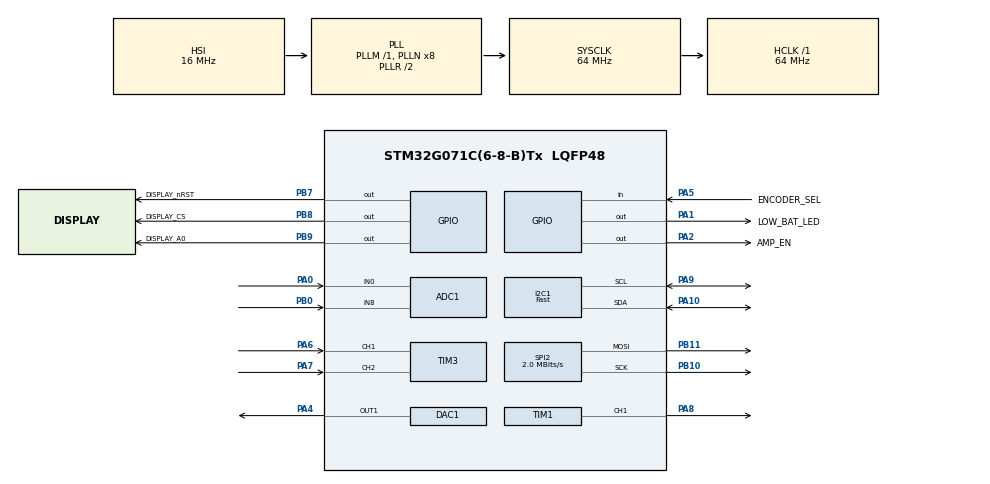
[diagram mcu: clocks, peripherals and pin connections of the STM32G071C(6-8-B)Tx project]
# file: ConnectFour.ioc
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ADC1.Channel-0\#ChannelRegularConversion=ADC_CHANNEL_0
ADC1.NbrOfConversionFlag=1
ADC1.Rank-0\#ChannelRegularConversion=1
ADC1.SamplingTime-0\#ChannelRegularConversion=ADC_SAMPLINGTIME_COMMON_1
ADC1.SamplingTimeCommon1=ADC_SAMPLETIME_160CYCLES_5
ADC1.SelectedChannel=ADC_CHANNEL_0|ADC_CHANNEL_8
ADC1.master=1
DAC1.DAC_Channel-DAC_OUT1=DAC_CHANNEL_1
DAC1.DAC_Trigger-DAC_OUT1=DAC_TRIGGER_T6_TRGO
Dma.DAC1_CH1.0.Direction=DMA_MEMORY_TO_PERIPH
Dma.DAC1_CH1.0.EventEnable=DISABLE
Dma.DAC1_CH1.0.Instance=DMA1_Channel1
Dma.DAC1_CH1.0.MemDataAlignment=DMA_MDATAALIGN_HALFWORD
Dma.DAC1_CH1.0.MemInc=DMA_MINC_ENABLE
Dma.DAC1_CH1.0.Mode=DMA_CIRCULAR
Dma.DAC1_CH1.0.PeriphDataAlignment=DMA_PDATAALIGN_HALFWORD
Dma.DAC1_CH1.0.PeriphInc=DMA_PINC_DISABLE
Dma.DAC1_CH1.0.Polarity=HAL_DMAMUX_REQ_GEN_RISING
Dma.DAC1_CH1.0.Priority=DMA_PRIORITY_HIGH
Dma.DAC1_CH1.0.RequestNumber=1
Dma.DAC1_CH1.0.SignalID=NONE
Dma.DAC1_CH1.0.SyncEnable=DISABLE
Dma.DAC1_CH1.0.SyncPolarity=HAL_DMAMUX_SYNC_NO_EVENT
Dma.DAC1_CH1.0.SyncRequestNumber=1
Dma.DAC1_CH1.0.SyncSignalID=NONE
Dma.Request0=DAC1_CH1
I2C1.I2C_Speed_Mode=I2C_Fast
I2C1.Timing=0x00C12166
Mcu.Family=STM32G0
Mcu.Name=STM32G071C(6-8-B)Tx
Mcu.Package=LQFP48
NVIC.DMA1_Channel1_IRQn=true\:0\:0\:false\:false\:true\:false\:true\:true
PA0.Mode=IN0
PA0.Signal=ADC1_IN0
PA1.GPIO_Label=LOW_BAT_LED
PA1.Signal=GPIO_Output
PA10.Mode=I2C
PA10.Signal=I2C1_SDA
PA13.Mode=Serial_Wire
PA13.Signal=SYS_SWDIO
PA14-BOOT0.Mode=Serial_Wire
PA14-BOOT0.Signal=SYS_SWCLK
PA2.GPIO_Label=AMP_EN
PA2.Signal=GPIO_Output
PA4.Signal=COMP_DAC11_group
PA5.GPIO_Label=ENCODER_SEL
PA5.Signal=GPIO_Input
PA6.Signal=S_TIM3_CH1
PA7.Signal=S_TIM3_CH2
PA8.Signal=S_TIM1_CH1
PA9.Mode=I2C
PA9.Signal=I2C1_SCL
PB0.Mode=IN8
PB0.Signal=ADC1_IN8
PB10.Mode=TX_Only_Simplex_Unidirect_Master
PB10.Signal=SPI2_SCK
PB11.Mode=TX_Only_Simplex_Unidirect_Master
PB11.Signal=SPI2_MOSI
PB7.GPIO_Label=DISPLAY_nRST
PB7.Signal=GPIO_Output
PB8.GPIO_Label=DISPLAY_CS
PB8.PinState=GPIO_PIN_SET
PB8.Signal=GPIO_Output
PB9.GPIO_Label=DISPLAY_A0
PB9.Signal=GPIO_Output
ProjectManager.HeapSize=0x200
ProjectManager.StackSize=0x1800
ProjectManager.TargetToolchain=CMake
RCC.ADCFreq_Value=64000000
RCC.AHBFreq_Value=64000000
RCC.CortexFreq_Value=64000000
RCC.EXTERNAL_CLOCK_VALUE=48000
RCC.HCLKFreq_Value=64000000
RCC.HSE_VALUE=8000000
RCC.HSI_VALUE=16000000
RCC.LSE_VALUE=32768
RCC.SYSCLKFreq_VALUE=64000000
RCC.SYSCLKSource=RCC_SYSCLKSOURCE_PLLCLK
RCC.VCOOutputFreq_Value=128000000
SH.COMP_DAC11_group.0=DAC1_OUT1,DAC_OUT1
SH.S_TIM1_CH1.0=TIM1_CH1,PWM Generation1 CH1
SH.S_TIM3_CH1.0=TIM3_CH1,Encoder_Interface
SH.S_TIM3_CH2.0=TIM3_CH2,Encoder_Interface
SPI2.BaudRatePrescaler=SPI_BAUDRATEPRESCALER_32
SPI2.CalculateBaudRate=2.0 MBits/s
SPI2.DataSize=SPI_DATASIZE_8BIT
SPI2.Direction=SPI_DIRECTION_2LINES
SPI2.Mode=SPI_MODE_MASTER
SPI2.NSSPMode=SPI_NSS_PULSE_DISABLE
SPI2.VirtualType=VM_MASTER
TIM1.AutoReloadPreload=TIM_AUTORELOAD_PRELOAD_ENABLE
TIM1.Channel-PWM\ Generation1\ CH1=TIM_CHANNEL_1
TIM1.Period=3199
TIM3.ClockDivision=TIM_CLOCKDIVISION_DIV4
TIM3.EncoderMode=TIM_ENCODERMODE_TI12
TIM3.IC1Filter=15
TIM3.IC2Filter=15
TIM6.AutoReloadPreload=TIM_AUTORELOAD_PRELOAD_ENABLE
TIM6.Period=3999
TIM6.TIM_MasterOutputTrigger=TIM_TRGO_UPDATE
VP_TIM1_VS_ClockSourceINT.Mode=Internal
VP_TIM6_VS_ClockSourceINT.Mode=Enable_Timer
board=custom

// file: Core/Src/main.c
/* USER CODE BEGIN Header */
/**
  ******************************************************************************
  * @file           : main.c
  * @brief          : Main program body
  ******************************************************************************
  * @attention
  *
  * Copyright (c) 2026 STMicroelectronics.
  * All rights reserved.
  *
  * This software is licensed under terms that can be found in the LICENSE file
  * in the root directory of this software component.
  * If no LICENSE file comes with this software, it is provided AS-IS.
  *
  ******************************************************************************
  */
/* USER CODE END Header */
#include "main.h"

/* USER CODE BEGIN Includes */
#include "app_main.h"
/* USER CODE END Includes */

ADC_HandleTypeDef hadc1;

DAC_HandleTypeDef hdac1;
DMA_HandleTypeDef hdma_dac1_ch1;

I2C_HandleTypeDef hi2c1;

SPI_HandleTypeDef hspi2;

TIM_HandleTypeDef htim1;
TIM_HandleTypeDef htim3;
TIM_HandleTypeDef htim6;

void SystemClock_Config(void);
static void MX_GPIO_Init(void);
static void MX_DMA_Init(void);
static void MX_ADC1_Init(void);
static void MX_DAC1_Init(void);
static void MX_I2C1_Init(void);
static void MX_SPI2_Init(void);
static void MX_TIM3_Init(void);
static void MX_TIM1_Init(void);
static void MX_TIM6_Init(void);

int main(void)
{

  /* MCU Configuration--------------------------------------------------------*/

  /* Reset of all peripherals, Initializes the Flash interface and the Systick. */
  HAL_Init();

  /* Configure the system clock */
  SystemClock_Config();

  /* Initialize all configured peripherals */
  MX_GPIO_Init();
  MX_DMA_Init();
  MX_ADC1_Init();
  MX_DAC1_Init();
  MX_I2C1_Init();
  MX_SPI2_Init();
  MX_TIM3_Init();
  MX_TIM1_Init();
  MX_TIM6_Init();
  /* USER CODE BEGIN 2 */
  app_main(); /* never returns */
  /* USER CODE END 2 */

  /* Infinite loop */
  while (1)
  {

  }
}

void SystemClock_Config(void)
{
  RCC_OscInitTypeDef RCC_OscInitStruct = {0};
  RCC_ClkInitTypeDef RCC_ClkInitStruct = {0};

  /** Configure the main internal regulator output voltage
  */
  HAL_PWREx_ControlVoltageScaling(PWR_REGULATOR_VOLTAGE_SCALE1);

  /** Initializes the RCC Oscillators according to the specified parameters
  * in the RCC_OscInitTypeDef structure.
  */
  RCC_OscInitStruct.OscillatorType = RCC_OSCILLATORTYPE_HSI;
  RCC_OscInitStruct.HSIState = RCC_HSI_ON;
  RCC_OscInitStruct.HSIDiv = RCC_HSI_DIV1;
  RCC_OscInitStruct.HSICalibrationValue = RCC_HSICALIBRATION_DEFAULT;
  RCC_OscInitStruct.PLL.PLLState = RCC_PLL_ON;
  RCC_OscInitStruct.PLL.PLLSource = RCC_PLLSOURCE_HSI;
  RCC_OscInitStruct.PLL.PLLM = RCC_PLLM_DIV1;
  RCC_OscInitStruct.PLL.PLLN = 8;
  RCC_OscInitStruct.PLL.PLLP = RCC_PLLP_DIV2;
  RCC_OscInitStruct.PLL.PLLQ = RCC_PLLQ_DIV2;
  RCC_OscInitStruct.PLL.PLLR = RCC_PLLR_DIV2;
  if (HAL_RCC_OscConfig(&RCC_OscInitStruct) != HAL_OK)
  {
    Error_Handler();
  }

  /** Initializes the CPU, AHB and APB buses clocks
  */
  RCC_ClkInitStruct.ClockType = RCC_CLOCKTYPE_HCLK|RCC_CLOCKTYPE_SYSCLK
                              |RCC_CLOCKTYPE_PCLK1;
  RCC_ClkInitStruct.SYSCLKSource = RCC_SYSCLKSOURCE_PLLCLK;
  RCC_ClkInitStruct.AHBCLKDivider = RCC_SYSCLK_DIV1;
  RCC_ClkInitStruct.APB1CLKDivider = RCC_HCLK_DIV1;

  if (HAL_RCC_ClockConfig(&RCC_ClkInitStruct, FLASH_LATENCY_2) != HAL_OK)
  {
    Error_Handler();
  }
}

static void MX_ADC1_Init(void)
{

  ADC_ChannelConfTypeDef sConfig = {0};

  /** Configure the global features of the ADC (Clock, Resolution, Data Alignment and number of conversion)
  */
  hadc1.Instance = ADC1;
  hadc1.Init.ClockPrescaler = ADC_CLOCK_SYNC_PCLK_DIV2;
  hadc1.Init.Resolution = ADC_RESOLUTION_12B;
  hadc1.Init.DataAlign = ADC_DATAALIGN_RIGHT;
  hadc1.Init.ScanConvMode = ADC_SCAN_DISABLE;
  hadc1.Init.EOCSelection = ADC_EOC_SINGLE_CONV;
  hadc1.Init.LowPowerAutoWait = DISABLE;
  hadc1.Init.LowPowerAutoPowerOff = DISABLE;
  hadc1.Init.ContinuousConvMode = DISABLE;
  hadc1.Init.NbrOfConversion = 1;
  hadc1.Init.DiscontinuousConvMode = DISABLE;
  hadc1.Init.ExternalTrigConv = ADC_SOFTWARE_START;
  hadc1.Init.ExternalTrigConvEdge = ADC_EXTERNALTRIGCONVEDGE_NONE;
  hadc1.Init.DMAContinuousRequests = DISABLE;
  hadc1.Init.Overrun = ADC_OVR_DATA_PRESERVED;
  hadc1.Init.SamplingTimeCommon1 = ADC_SAMPLETIME_160CYCLES_5;
  hadc1.Init.SamplingTimeCommon2 = ADC_SAMPLETIME_1CYCLE_5;
  hadc1.Init.OversamplingMode = DISABLE;
  hadc1.Init.TriggerFrequencyMode = ADC_TRIGGER_FREQ_HIGH;
  if (HAL_ADC_Init(&hadc1) != HAL_OK)
  {
    Error_Handler();
  }

  /** Configure Regular Channel
  */
  sConfig.Channel = ADC_CHANNEL_0;
  sConfig.Rank = ADC_REGULAR_RANK_1;
  sConfig.SamplingTime = ADC_SAMPLINGTIME_COMMON_1;
  if (HAL_ADC_ConfigChannel(&hadc1, &sConfig) != HAL_OK)
  {
    Error_Handler();
  }

}

static void MX_DAC1_Init(void)
{

  DAC_ChannelConfTypeDef sConfig = {0};

  /** DAC Initialization
  */
  hdac1.Instance = DAC1;
  if (HAL_DAC_Init(&hdac1) != HAL_OK)
  {
    Error_Handler();
  }

  /** DAC channel OUT1 config
  */
  sConfig.DAC_SampleAndHold = DAC_SAMPLEANDHOLD_DISABLE;
  sConfig.DAC_Trigger = DAC_TRIGGER_T6_TRGO;
  sConfig.DAC_OutputBuffer = DAC_OUTPUTBUFFER_ENABLE;
  sConfig.DAC_ConnectOnChipPeripheral = DAC_CHIPCONNECT_DISABLE;
  sConfig.DAC_UserTrimming = DAC_TRIMMING_FACTORY;
  if (HAL_DAC_ConfigChannel(&hdac1, &sConfig, DAC_CHANNEL_1) != HAL_OK)
  {
    Error_Handler();
  }

}

static void MX_I2C1_Init(void)
{

  hi2c1.Instance = I2C1;
  hi2c1.Init.Timing = 0x00C12166;
  hi2c1.Init.OwnAddress1 = 0;
  hi2c1.Init.AddressingMode = I2C_ADDRESSINGMODE_7BIT;
  hi2c1.Init.DualAddressMode = I2C_DUALADDRESS_DISABLE;
  hi2c1.Init.OwnAddress2 = 0;
  hi2c1.Init.OwnAddress2Masks = I2C_OA2_NOMASK;
  hi2c1.Init.GeneralCallMode = I2C_GENERALCALL_DISABLE;
  hi2c1.Init.NoStretchMode = I2C_NOSTRETCH_DISABLE;
  if (HAL_I2C_Init(&hi2c1) != HAL_OK)
  {
    Error_Handler();
  }

  /** Configure Analogue filter
  */
  if (HAL_I2CEx_ConfigAnalogFilter(&hi2c1, I2C_ANALOGFILTER_ENABLE) != HAL_OK)
  {
    Error_Handler();
  }

  /** Configure Digital filter
  */
  if (HAL_I2CEx_ConfigDigitalFilter(&hi2c1, 0) != HAL_OK)
  {
    Error_Handler();
  }

}

static void MX_SPI2_Init(void)
{

  /* SPI2 parameter configuration*/
  hspi2.Instance = SPI2;
  hspi2.Init.Mode = SPI_MODE_MASTER;
  hspi2.Init.Direction = SPI_DIRECTION_2LINES;
  hspi2.Init.DataSize = SPI_DATASIZE_8BIT;
  hspi2.Init.CLKPolarity = SPI_POLARITY_LOW;
  hspi2.Init.CLKPhase = SPI_PHASE_1EDGE;
  hspi2.Init.NSS = SPI_NSS_SOFT;
  hspi2.Init.BaudRatePrescaler = SPI_BAUDRATEPRESCALER_32;
  hspi2.Init.FirstBit = SPI_FIRSTBIT_MSB;
  hspi2.Init.TIMode = SPI_TIMODE_DISABLE;
  hspi2.Init.CRCCalculation = SPI_CRCCALCULATION_DISABLE;
  hspi2.Init.CRCPolynomial = 7;
  hspi2.Init.CRCLength = SPI_CRC_LENGTH_DATASIZE;
  hspi2.Init.NSSPMode = SPI_NSS_PULSE_DISABLE;
  if (HAL_SPI_Init(&hspi2) != HAL_OK)
  {
    Error_Handler();
  }

}

static void MX_TIM1_Init(void)
{

  TIM_ClockConfigTypeDef sClockSourceConfig = {0};
  TIM_MasterConfigTypeDef sMasterConfig = {0};
  TIM_OC_InitTypeDef sConfigOC = {0};
  TIM_BreakDeadTimeConfigTypeDef sBreakDeadTimeConfig = {0};

  htim1.Instance = TIM1;
  htim1.Init.Prescaler = 0;
  htim1.Init.CounterMode = TIM_COUNTERMODE_UP;
  htim1.Init.Period = 3199;
  htim1.Init.ClockDivision = TIM_CLOCKDIVISION_DIV1;
  htim1.Init.RepetitionCounter = 0;
  htim1.Init.AutoReloadPreload = TIM_AUTORELOAD_PRELOAD_ENABLE;
  if (HAL_TIM_Base_Init(&htim1) != HAL_OK)
  {
    Error_Handler();
  }
  sClockSourceConfig.ClockSource = TIM_CLOCKSOURCE_INTERNAL;
  if (HAL_TIM_ConfigClockSource(&htim1, &sClockSourceConfig) != HAL_OK)
  {
    Error_Handler();
  }
  if (HAL_TIM_PWM_Init(&htim1) != HAL_OK)
  {
    Error_Handler();
  }
  sMasterConfig.MasterOutputTrigger = TIM_TRGO_RESET;
  sMasterConfig.MasterOutputTrigger2 = TIM_TRGO2_RESET;
  sMasterConfig.MasterSlaveMode = TIM_MASTERSLAVEMODE_DISABLE;
  if (HAL_TIMEx_MasterConfigSynchronization(&htim1, &sMasterConfig) != HAL_OK)
  {
    Error_Handler();
  }
  sConfigOC.OCMode = TIM_OCMODE_PWM1;
  sConfigOC.Pulse = 0;
  sConfigOC.OCPolarity = TIM_OCPOLARITY_HIGH;
  sConfigOC.OCNPolarity = TIM_OCNPOLARITY_HIGH;
  sConfigOC.OCFastMode = TIM_OCFAST_DISABLE;
  sConfigOC.OCIdleState = TIM_OCIDLESTATE_RESET;
  sConfigOC.OCNIdleState = TIM_OCNIDLESTATE_RESET;
  if (HAL_TIM_PWM_ConfigChannel(&htim1, &sConfigOC, TIM_CHANNEL_1) != HAL_OK)
  {
    Error_Handler();
  }
  sBreakDeadTimeConfig.OffStateRunMode = TIM_OSSR_DISABLE;
  sBreakDeadTimeConfig.OffStateIDLEMode = TIM_OSSI_DISABLE;
  sBreakDeadTimeConfig.LockLevel = TIM_LOCKLEVEL_OFF;
  sBreakDeadTimeConfig.DeadTime = 0;
  sBreakDeadTimeConfig.BreakState = TIM_BREAK_DISABLE;
  sBreakDeadTimeConfig.BreakPolarity = TIM_BREAKPOLARITY_HIGH;
  sBreakDeadTimeConfig.BreakFilter = 0;
  sBreakDeadTimeConfig.BreakAFMode = TIM_BREAK_AFMODE_INPUT;
  sBreakDeadTimeConfig.Break2State = TIM_BREAK2_DISABLE;
  sBreakDeadTimeConfig.Break2Polarity = TIM_BREAK2POLARITY_HIGH;
  sBreakDeadTimeConfig.Break2Filter = 0;
  sBreakDeadTimeConfig.Break2AFMode = TIM_BREAK_AFMODE_INPUT;
  sBreakDeadTimeConfig.AutomaticOutput = TIM_AUTOMATICOUTPUT_DISABLE;
  if (HAL_TIMEx_ConfigBreakDeadTime(&htim1, &sBreakDeadTimeConfig) != HAL_OK)
  {
    Error_Handler();
  }
  HAL_TIM_MspPostInit(&htim1);

}

static void MX_TIM3_Init(void)
{

  TIM_Encoder_InitTypeDef sConfig = {0};
  TIM_MasterConfigTypeDef sMasterConfig = {0};

  htim3.Instance = TIM3;
  htim3.Init.Prescaler = 0;
  htim3.Init.CounterMode = TIM_COUNTERMODE_UP;
  htim3.Init.Period = 65535;
  htim3.Init.ClockDivision = TIM_CLOCKDIVISION_DIV4;
  htim3.Init.AutoReloadPreload = TIM_AUTORELOAD_PRELOAD_DISABLE;
  sConfig.EncoderMode = TIM_ENCODERMODE_TI12;
  sConfig.IC1Polarity = TIM_ICPOLARITY_RISING;
  sConfig.IC1Selection = TIM_ICSELECTION_DIRECTTI;
  sConfig.IC1Prescaler = TIM_ICPSC_DIV1;
  sConfig.IC1Filter = 15;
  sConfig.IC2Polarity = TIM_ICPOLARITY_RISING;
  sConfig.IC2Selection = TIM_ICSELECTION_DIRECTTI;
  sConfig.IC2Prescaler = TIM_ICPSC_DIV1;
  sConfig.IC2Filter = 15;
  if (HAL_TIM_Encoder_Init(&htim3, &sConfig) != HAL_OK)
  {
    Error_Handler();
  }
  sMasterConfig.MasterOutputTrigger = TIM_TRGO_RESET;
  sMasterConfig.MasterSlaveMode = TIM_MASTERSLAVEMODE_DISABLE;
  if (HAL_TIMEx_MasterConfigSynchronization(&htim3, &sMasterConfig) != HAL_OK)
  {
    Error_Handler();
  }

}

static void MX_TIM6_Init(void)
{

  TIM_MasterConfigTypeDef sMasterConfig = {0};

  htim6.Instance = TIM6;
  htim6.Init.Prescaler = 0;
  htim6.Init.CounterMode = TIM_COUNTERMODE_UP;
  htim6.Init.Period = 3999;
  htim6.Init.AutoReloadPreload = TIM_AUTORELOAD_PRELOAD_ENABLE;
  if (HAL_TIM_Base_Init(&htim6) != HAL_OK)
  {
    Error_Handler();
  }
  sMasterConfig.MasterOutputTrigger = TIM_TRGO_UPDATE;
  sMasterConfig.MasterSlaveMode = TIM_MASTERSLAVEMODE_DISABLE;
  if (HAL_TIMEx_MasterConfigSynchronization(&htim6, &sMasterConfig) != HAL_OK)
  {
    Error_Handler();
  }

}

static void MX_DMA_Init(void)
{

  /* DMA controller clock enable */
  __HAL_RCC_DMA1_CLK_ENABLE();

  /* DMA interrupt init */
  /* DMA1_Channel1_IRQn interrupt configuration */
  HAL_NVIC_SetPriority(DMA1_Channel1_IRQn, 0, 0);
  HAL_NVIC_EnableIRQ(DMA1_Channel1_IRQn);

}

static void MX_GPIO_Init(void)
{
  GPIO_InitTypeDef GPIO_InitStruct = {0};

  /* GPIO Ports Clock Enable */
  __HAL_RCC_GPIOA_CLK_ENABLE();
  __HAL_RCC_GPIOB_CLK_ENABLE();

  /*Configure GPIO pin Output Level */
  HAL_GPIO_WritePin(GPIOA, LOW_BAT_LED_Pin|AMP_EN_Pin, GPIO_PIN_RESET);

  /*Configure GPIO pin Output Level */
  HAL_GPIO_WritePin(GPIOB, DISPLAY_nRST_Pin|DISPLAY_A0_Pin, GPIO_PIN_RESET);

  /*Configure GPIO pin Output Level */
  HAL_GPIO_WritePin(DISPLAY_CS_GPIO_Port, DISPLAY_CS_Pin, GPIO_PIN_SET);

  /*Configure GPIO pins : LOW_BAT_LED_Pin AMP_EN_Pin */
  GPIO_InitStruct.Pin = LOW_BAT_LED_Pin|AMP_EN_Pin;
  GPIO_InitStruct.Mode = GPIO_MODE_OUTPUT_PP;
  GPIO_InitStruct.Pull = GPIO_NOPULL;
  GPIO_InitStruct.Speed = GPIO_SPEED_FREQ_LOW;
  HAL_GPIO_Init(GPIOA, &GPIO_InitStruct);

  /*Configure GPIO pin : ENCODER_SEL_Pin */
  GPIO_InitStruct.Pin = ENCODER_SEL_Pin;
  GPIO_InitStruct.Mode = GPIO_MODE_INPUT;
  GPIO_InitStruct.Pull = GPIO_NOPULL;
  HAL_GPIO_Init(ENCODER_SEL_GPIO_Port, &GPIO_InitStruct);

  /*Configure GPIO pins : DISPLAY_nRST_Pin DISPLAY_CS_Pin DISPLAY_A0_Pin */
  GPIO_InitStruct.Pin = DISPLAY_nRST_Pin|DISPLAY_CS_Pin|DISPLAY_A0_Pin;
  GPIO_InitStruct.Mode = GPIO_MODE_OUTPUT_PP;
  GPIO_InitStruct.Pull = GPIO_NOPULL;
  GPIO_InitStruct.Speed = GPIO_SPEED_FREQ_LOW;
  HAL_GPIO_Init(GPIOB, &GPIO_InitStruct);

}

void Error_Handler(void)
{
  __disable_irq();
  while (1)
  {
  }
}
